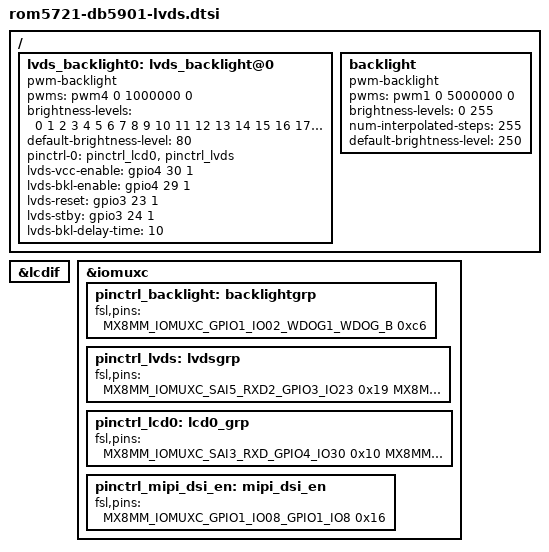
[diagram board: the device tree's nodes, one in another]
#include "rom5721-db5901.dtsi"

/ {
	lvds_backlight0: lvds_backlight@0 {
                compatible = "pwm-backlight";
                pwms = <&pwm4 0 1000000 0>;
                brightness-levels = < 0  1  2  3  4  5  6  7  8  9
                             10 11 12 13 14 15 16 17 18 19
                             20 21 22 23 24 25 26 27 28 29
                             30 31 32 33 34 35 36 37 38 39
                             40 41 42 43 44 45 46 47 48 49
                             50 51 52 53 54 55 56 57 58 59
                             60 61 62 63 64 65 66 67 68 69
                             70 71 72 73 74 75 76 77 78 79
                             80 81 82 83 84 85 86 87 88 89
                             90 91 92 93 94 95 96 97 98 99
                            100>;
                default-brightness-level = <80>;
    };

	backlight: backlight {
		compatible = "pwm-backlight";
		pwms = <&pwm1 0 5000000 0>;
		brightness-levels = <0 255>;
		num-interpolated-steps = <255>;
		default-brightness-level = <250>;
	};

};

&lvds_backlight0 {
        pinctrl-names = "default";
        pinctrl-0 = <&pinctrl_lcd0>,<&pinctrl_lvds>;
        lvds-vcc-enable = <&gpio4 30 1>;
        lvds-bkl-enable = <&gpio4 29 1>;
        lvds-reset=<&gpio3 23 1>;
        lvds-stby=<&gpio3 24 1>;
        lvds-bkl-delay-time = <10>;
        status = "okay";
};

&lcdif {
       status = "okay";
};

&iomuxc {
	pinctrl_backlight: backlightgrp {
		fsl,pins = <
			MX8MM_IOMUXC_GPIO1_IO02_WDOG1_WDOG_B		0xc6	/* PMIC_WDOG */
		>;
	};

	pinctrl_lvds: lvdsgrp {
        fsl,pins = <
            MX8MM_IOMUXC_SAI5_RXD2_GPIO3_IO23	0x19	/* LVDS_STBY */
            MX8MM_IOMUXC_SAI5_RXD3_GPIO3_IO24	0x19	/* LVDS_RESET */
        >;
    };

    pinctrl_lcd0: lcd0_grp {
        fsl,pins = <
            MX8MM_IOMUXC_SAI3_RXD_GPIO4_IO30	0x10		/* LCD0_VDD_EN */
            MX8MM_IOMUXC_SAI3_RXC_GPIO4_IO29	0x19		/* LCD0_BKLT_EN */
        >;
    };

	pinctrl_mipi_dsi_en: mipi_dsi_en {
        fsl,pins = <
            MX8MM_IOMUXC_GPIO1_IO08_GPIO1_IO8		0x16
        >;
	};
};
